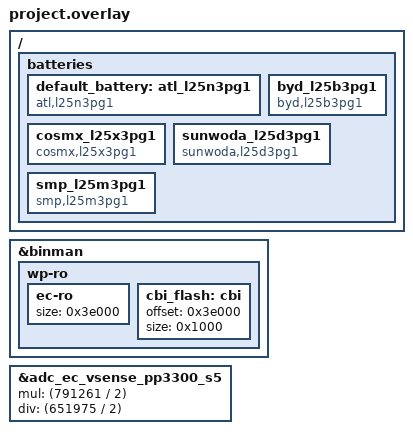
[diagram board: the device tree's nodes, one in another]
/* Copyright 2025 The ChromiumOS Authors
 * Use of this source code is governed by a BSD-style license that can be
 * found in the LICENSE file.
 */

#include <cros/cbi_flash.dtsi>

/* Trulo program common DTS includes */
#include "../generated.dtsi"
#include "../i2c.dtsi"
#include "../power_signals.dtsi"
#include "../usba.dtsi"

/* Trulo project DTS includes*/
#include "cbi.dtsi"
#include "gpio.dtsi"
#include "keyboard.dtsi"
#include "led_pins.dtsi"
#include "led_policy.dtsi"
#include "temp_sensors.dtsi"
#include "usb_typec.dtsi"


/* Trulo overrides follow... */

/ {
    batteries {
		default_battery: atl_l25n3pg1 {
			compatible = "atl,l25n3pg1", "battery-smart";
		};
		byd_l25b3pg1 {
			compatible = "byd,l25b3pg1", "battery-smart";
		};
		cosmx_l25x3pg1 {
			compatible = "cosmx,l25x3pg1", "battery-smart";
		};
		sunwoda_l25d3pg1 {
			compatible = "sunwoda,l25d3pg1", "battery-smart";
		};
		smp_l25m3pg1 {
			compatible = "smp,l25m3pg1", "battery-smart";
		};
    };
};

&binman {
	wp-ro {
		ec-ro {
			size = <0x3e000>;
		};
		cbi_flash: cbi {
			/*
			 * CBI section size is 0x1000 bytes, the
			 * CBI portion lies at the end of EC_RO section.
			 */
			offset = <0x3e000>;
			size = <0x1000>;
		};
	};
};

&adc_ec_vsense_pp3300_s5 {
	/*
	 * Voltage divider on input has 47k upper and 220k lower legs with
	 * 2714 mV full-scale reading on the ADC. Apply the largest possible
	 * multiplier (without overflowing int32) to get the best possible
	 * approximation of the actual ratio, but derate by a factor of two to
	 * ensure unexpectedly high values won't overflow.
	 */
	mul = <(791261 / 2)>;
	div = <(651975 / 2)>;
};
